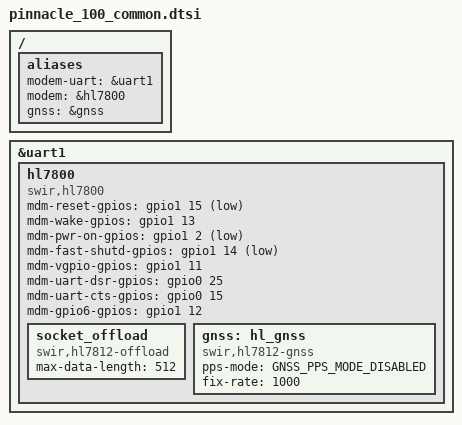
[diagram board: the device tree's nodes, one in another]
/delete-node/ &hl7800;

/ {
	aliases {
		modem-uart = &uart1;
		modem = &hl7800;
		gnss = &gnss;
	};
};

&uart1 {
	hl7800: hl7800 {
		compatible = "swir,hl7800";
		status = "okay";
		mdm-reset-gpios = <&gpio1 15 (GPIO_OPEN_DRAIN | GPIO_ACTIVE_LOW)>;
		mdm-wake-gpios = <&gpio1 13 (GPIO_OPEN_SOURCE | GPIO_ACTIVE_HIGH)>;
		mdm-pwr-on-gpios = <&gpio1 2 (GPIO_OPEN_DRAIN | GPIO_ACTIVE_LOW)>;
		mdm-fast-shutd-gpios = <&gpio1 14 (GPIO_OPEN_DRAIN | GPIO_ACTIVE_LOW)>;
		mdm-vgpio-gpios = <&gpio1 11 0>;
		mdm-uart-dsr-gpios = <&gpio0 25 0>;
		mdm-uart-cts-gpios = <&gpio0 15 0>;
		mdm-gpio6-gpios = <&gpio1 12 0>;
		socket_offload: socket_offload {
			compatible = "swir,hl7812-offload";
			status = "okay";
			/* optional properties for future: */
			max-data-length = <512>;
		};
		gnss: hl_gnss {
			compatible = "swir,hl7812-gnss";
			pps-mode = "GNSS_PPS_MODE_DISABLED";
			fix-rate = <1000>;
			status = "okay";
		};
	};
};
